# ATSAMG51N18 device description
Architecture: CORTEX-M4; Family: SAMG; Series: SAMG51
Registers are 32-bit, access not given, no defined reset value unless marked. A register's access mark holds for its fields unless they carry their own. Offsets are from the block's base; [hi:lo] are bit positions.

## UART — Universal Asynchronous Receiver Transmitter
Instances: UART0 0x400E0600, UART1 0x400E0800
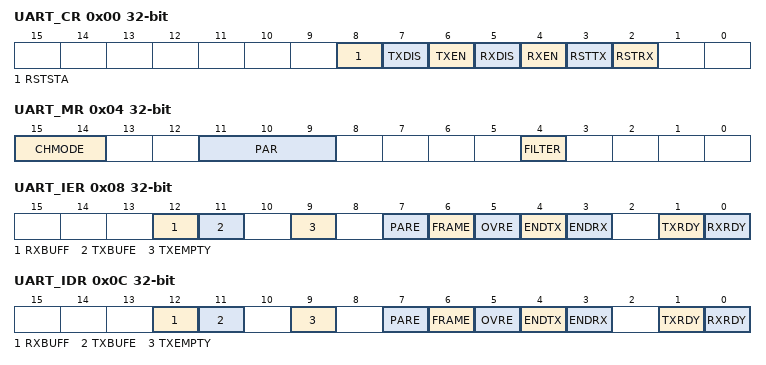
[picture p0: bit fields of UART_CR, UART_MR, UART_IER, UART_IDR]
0x00 UART_CR wo — Control Register
  [8] RSTSTA — Reset Status
  [7] TXDIS — Transmitter Disable
  [6] TXEN — Transmitter Enable
  [5] RXDIS — Receiver Disable
  [4] RXEN — Receiver Enable
  [3] RSTTX — Reset Transmitter
  [2] RSTRX — Reset Receiver
0x04 UART_MR rw — Mode Register
  [15:14] CHMODE — Channel Mode
    0=NORMAL (Normal mode); 1=AUTOMATIC (Automatic echo); 2=LOCAL_LOOPBACK; 3=REMOTE_LOOPBACK
  [11:9] PAR — Parity Type
    0=EVEN (Even Parity); 1=ODD (Odd Parity); 2=SPACE (Space: parity forced to 0); 3=MARK (Mark: parity forced to 1); 4=NO (No parity)
  [4] FILTER — Receiver Digital Filter
    0=DISABLED (UART does not filter the receive line.); 1=ENABLED (UART filters the receive line using a three-sample filter (16x-bit clock) (2 over 3 majority).)
0x08 UART_IER wo (atomic set of UART_IMR) — Interrupt Enable Register
  [12] RXBUFF — Enable Buffer Full Interrupt
  [11] TXBUFE — Enable Buffer Empty Interrupt
  [9] TXEMPTY — Enable TXEMPTY Interrupt
  [7] PARE — Enable Parity Error Interrupt
  [6] FRAME — Enable Framing Error Interrupt
  [5] OVRE — Enable Overrun Error Interrupt
  [4] ENDTX — Enable End of Transmit Interrupt
  [3] ENDRX — Enable End of Receive Transfer Interrupt
  [1] TXRDY — Enable TXRDY Interrupt
  [0] RXRDY — Enable RXRDY Interrupt
0x0C UART_IDR wo (atomic clear of UART_IMR) — Interrupt Disable Register
  [12] RXBUFF — Disable Buffer Full Interrupt
  [11] TXBUFE — Disable Buffer Empty Interrupt
  [9] TXEMPTY — Disable TXEMPTY Interrupt
  [7] PARE — Disable Parity Error Interrupt
  [6] FRAME — Disable Framing Error Interrupt
  [5] OVRE — Disable Overrun Error Interrupt
  [4] ENDTX — Disable End of Transmit Interrupt
  [3] ENDRX — Disable End of Receive Transfer Interrupt
  [1] TXRDY — Disable TXRDY Interrupt
  [0] RXRDY — Disable RXRDY Interrupt
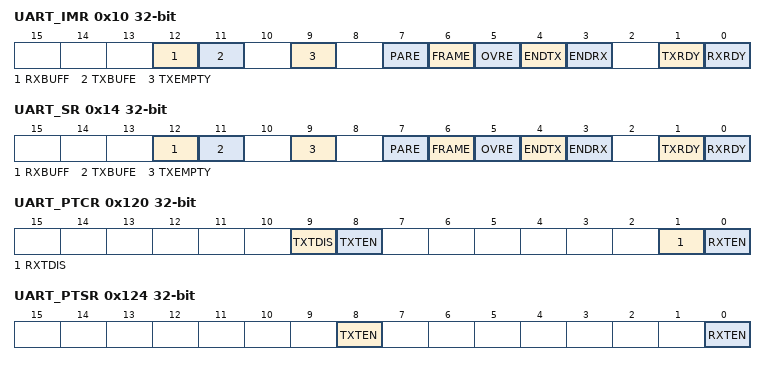
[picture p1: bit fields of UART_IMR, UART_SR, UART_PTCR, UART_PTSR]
0x10 UART_IMR ro (atomic read) — Interrupt Mask Register
  [12] RXBUFF — Mask RXBUFF Interrupt
  [11] TXBUFE — Mask TXBUFE Interrupt
  [9] TXEMPTY — Mask TXEMPTY Interrupt
  [7] PARE — Mask Parity Error Interrupt
  [6] FRAME — Mask Framing Error Interrupt
  [5] OVRE — Mask Overrun Error Interrupt
  [4] ENDTX — Mask End of Transmit Interrupt
  [3] ENDRX — Mask End of Receive Transfer Interrupt
  [1] TXRDY — Disable TXRDY Interrupt
  [0] RXRDY — Mask RXRDY Interrupt
0x14 UART_SR ro — Status Register
  [12] RXBUFF — Receive Buffer Full
  [11] TXBUFE — Transmission Buffer Empty
  [9] TXEMPTY — Transmitter Empty
  [7] PARE — Parity Error
  [6] FRAME — Framing Error
  [5] OVRE — Overrun Error
  [4] ENDTX — End of Transmitter Transfer
  [3] ENDRX — End of Receiver Transfer
  [1] TXRDY — Transmitter Ready
  [0] RXRDY — Receiver Ready
0x18 UART_RHR ro — Receive Holding Register
  [7:0] RXCHR — Received Character
0x1C UART_THR wo — Transmit Holding Register
  [7:0] TXCHR — Character to be Transmitted
0x20 UART_BRGR rw — Baud Rate Generator Register
  [15:0] CD — Clock Divisor
0x100 UART_RPR rw — Receive Pointer Register
  [31:0] RXPTR
0x104 UART_RCR rw — Receive Counter Register
  [15:0] RXCTR
0x108 UART_TPR rw — Transmit Pointer Register
  [31:0] TXPTR — Transmit Counter Register
0x10C UART_TCR rw — Transmit Counter Register
  [15:0] TXCTR
0x110 UART_RNPR rw — Receive Next Pointer Register
  [31:0] RXNPTR — Receive Next Pointer
0x114 UART_RNCR rw — Receive Next Counter Register
  [15:0] RXNCTR — Receive Next Counter
0x118 UART_TNPR rw — Transmit Next Pointer Register
  [31:0] TXNPTR — Transmit Next Pointer
0x11C UART_TNCR rw — Transmit Next Counter Register
  [15:0] TXNCTR — Transmit Counter Next
0x120 UART_PTCR wo — Transfer Control Register
  [9] TXTDIS — Transmitter Transfer Disable
  [8] TXTEN — Transmitter Transfer Enable
  [1] RXTDIS — Receiver Transfer Disable
  [0] RXTEN — Receiver Transfer Enable
0x124 UART_PTSR ro — Transfer Status Register
  [8] TXTEN — Transmitter Transfer Enable
  [0] RXTEN — Receiver Transfer Enable
